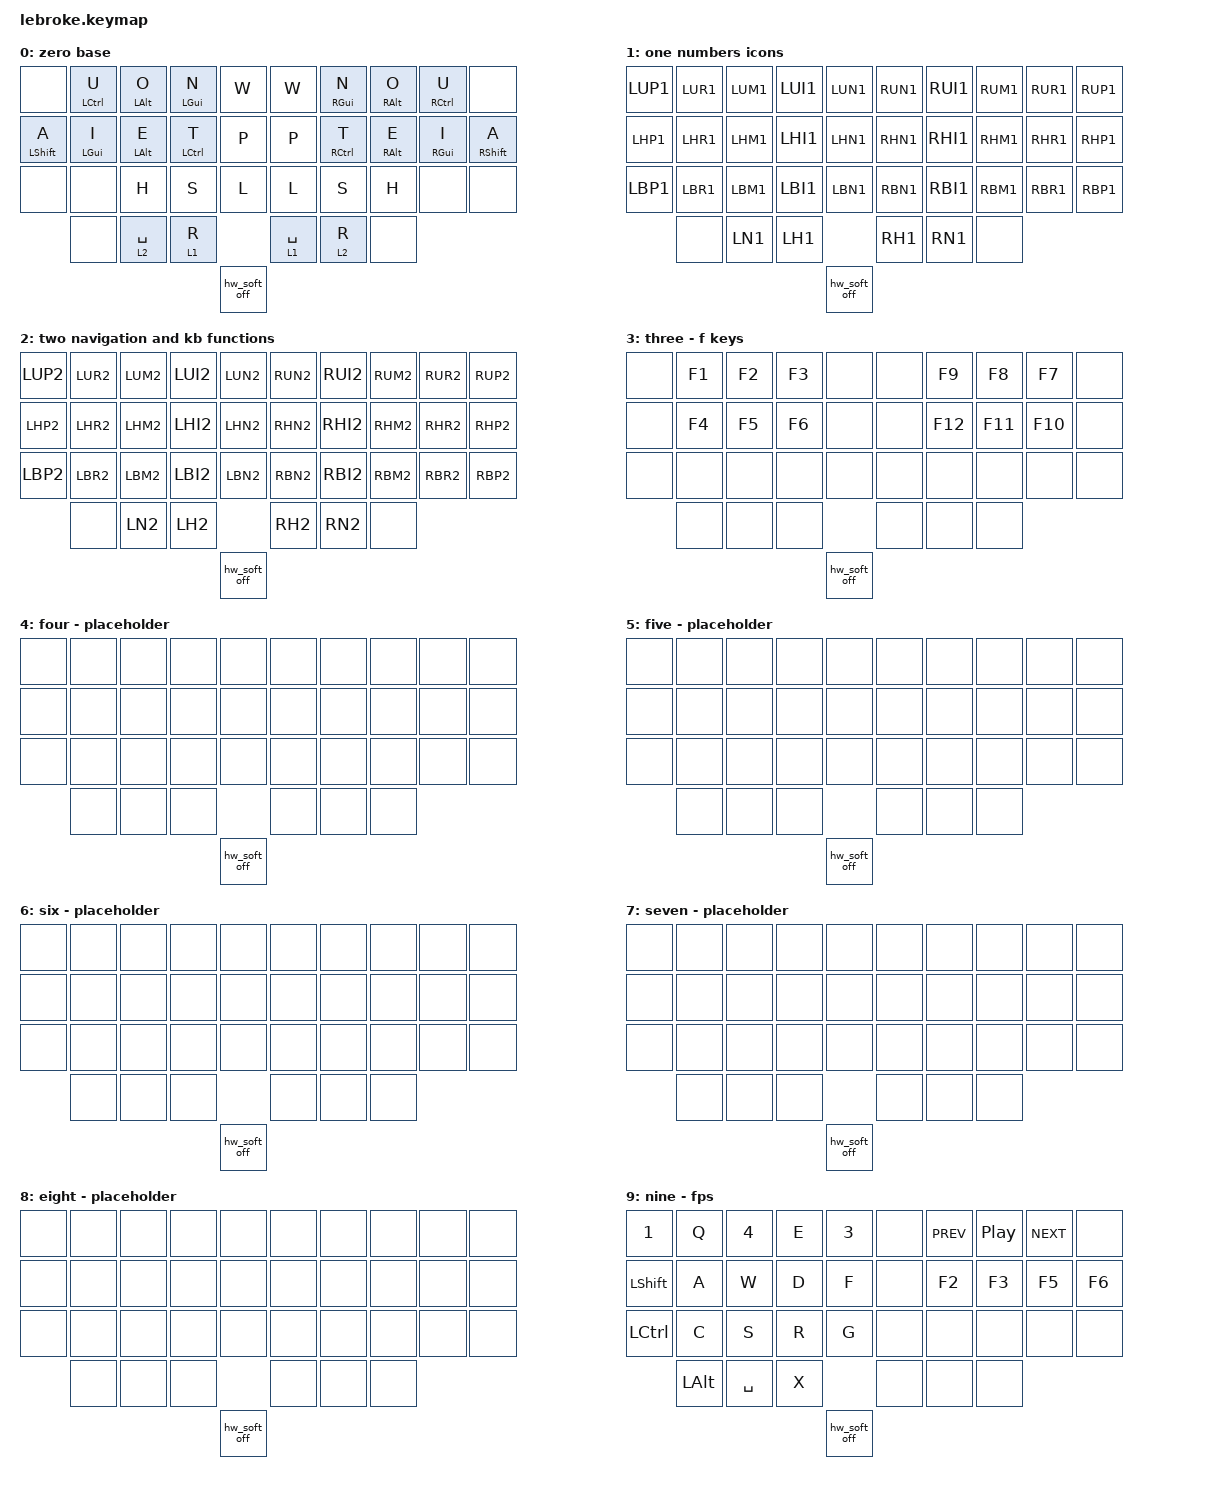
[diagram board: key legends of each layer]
#include "fingermap.h"

/ {
	behaviors {
		hml: home_row_mod_left {
            		hold-trigger-key-positions = <5 6 7 8 9 15 16 17 18 19 25 26 27 28 29 33 34 35>; // List of keys on the right
        	};
        	hmr: home_row_mod_right {
            		hold-trigger-key-positions = <0 1 2 3 4 10 11 12 13 14 20 21 22 23 24 30 31 32>; // List of keys on the left
       		};
	};
	keymap {
		compatible = "zmk,keymap";
		zero {
			display-name = "zero base";
			bindings = <
				&none &hml LCTRL U &hml LALT O &hml LGUI N &kp W &kp W &hmr RGUI N &hmr RALT O &hmr RCTRL U &none
				&hml LSHIFT A &hml LGUI I &hml LALT E &hml LCTRL T &kp P &kp P &hmr RCTRL T &hmr RALT E &hmr RGUI I &hmr RSHIFT A
				&none &none &kp H &kp S &kp L &kp L &kp S &kp H &none &none
				&none &lt 2 SPACE &lt 1 R &lt 1 SPACE &lt 2 R &none
									&hw_soft_off
			>;
		};
		one { display-name = "one numbers icons";
			bindings = <
				LUP1 LUR1 LUM1 LUI1 LUN1 RUN1 RUI1 RUM1 RUR1 RUP1
				LHP1 LHR1 LHM1 LHI1 LHN1 RHN1 RHI1 RHM1 RHR1 RHP1
				LBP1 LBR1 LBM1 LBI1 LBN1 RBN1 RBI1 RBM1 RBR1 RBP1
					   &none LN1 LH1 RH1 RN1 &none 	
									&hw_soft_off
			>;
		};
		two { display-name = "two navigation and kb functions";
			bindings = <
				LUP2 LUR2 LUM2 LUI2 LUN2 RUN2 RUI2 RUM2 RUR2 RUP2
				LHP2 LHR2 LHM2 LHI2 LHN2 RHN2 RHI2 RHM2 RHR2 RHP2
				LBP2 LBR2 LBM2 LBI2 LBN2 RBN2 RBI2 RBM2 RBR2 RBP2
					   &none LN2 LH2 RH2 RN2 &none 	
									&hw_soft_off
			>;
		};
		three { display-name = "three - f keys";
			bindings = <
				&none &kp F1 &kp F2 &kp F3 &none &none &kp F9 &kp F8 &kp F7 &none
				&none &kp F4 &kp F5 &kp F6 &none &none &kp F12 &kp F11 &kp F10 &none
				&none &none &none &none &none &none &none &none &none &none
				&none &none &none &none &none &none &hw_soft_off
			>;
		};
		four { display-name = "four - placeholder";
			bindings = <
				&none &none &none &none &none &none &none &none &none &none
				&none &none &none &none &none &none &none &none &none &none
				&none &none &none &none &none &none &none &none &none &none
				&none &none &none &none &none &none &hw_soft_off
			>;
		};
		five { display-name = "five - placeholder";
			bindings = <
				&none &none &none &none &none &none &none &none &none &none
				&none &none &none &none &none &none &none &none &none &none
				&none &none &none &none &none &none &none &none &none &none
				&none &none &none &none &none &none &hw_soft_off
			>;
		};
		six { display-name = "six - placeholder";
			bindings = <
				&none &none &none &none &none &none &none &none &none &none
				&none &none &none &none &none &none &none &none &none &none
				&none &none &none &none &none &none &none &none &none &none
				&none &none &none &none &none &none &hw_soft_off
			>;
		};
		seven { display-name = "seven - placeholder";
			bindings = <
				&none &none &none &none &none &none &none &none &none &none
				&none &none &none &none &none &none &none &none &none &none
				&none &none &none &none &none &none &none &none &none &none
				&none &none &none &none &none &none &hw_soft_off
			>;
		};
		eight { display-name = "eight - placeholder";
			bindings = <
				&none &none &none &none &none &none &none &none &none &none
				&none &none &none &none &none &none &none &none &none &none
				&none &none &none &none &none &none &none &none &none &none
				&none &none &none &none &none &none &hw_soft_off
			>;
		};
		nine { display-name = "nine - fps";
			bindings = <
				&kp N1 &kp Q &kp N4 &kp E &kp N3 		&none &kp C_PREV &kp C_PP &kp C_NEXT &none
				&kp LSHIFT &kp A &kp W &kp D &kp F 		&none &kp F2 &kp F3 &kp F5 &kp F6
				&kp LCTRL &kp C &kp S &kp R &kp G		&none &none &none &none &none
				&kp LALT &kp SPACE &kp X 			&none &none &none &hw_soft_off
			>;
		};
	};
};

/ {
	combos {
		compatible = "zmk,combos";

// keyboard functions
		combo_bt_zero {
			timeout-ms = <50>;
			key-positions = <10 11 12 13>;
			bindings = <&bluetooth0>;
			layers = <0>;
		};
		combo_bt_one {
			timeout-ms = <50>;
			key-positions = <16 17 18 19>;
			bindings = <&bluetooth1>;
			layers = <0>;
		};
		combo_usb {
			timeout-ms = <50>;
			key-positions = <22 23 26 27>;
			bindings = <&out OUT_USB>;
			layers = <0>;
		};
		combo_fps_layer {
			timeout-ms = <50>;
			key-positions = <11 12 13>;
			bindings = <&to 9>;
			layers = <0>;
		};
		combo_default_layer {
			timeout-ms = <50>;
			key-positions = <12 13 16 17>;
			bindings = <&to 0>;
		};
// mod keys


		combo_lhp_lhr {
			timeout-ms = <50>;
			key-positions = <10 11>;
			bindings = <LHO>;
			layers = <0 1 2>;
		};
		combo_lur_lui {
			timeout-ms = <50>;
			key-positions = <1 3>;
			bindings = <LUO>;
		};
		combo_rui_rur {
			timeout-ms = <50>;
			key-positions = <6 8>;
			bindings = <RUO>;
		};
		combo_rhr_rhp {
			timeout-ms = <50>;
			key-positions = <18 19>;
			bindings = <RHO>;
			layers = <0 1 2>;
		};


		combo_enter {
			timeout-ms = <50>;
			key-positions = <13 16>;
			bindings = <&kp ENTER>;
			layers = <0 1 2>;
		};
		combo_capsword {
			timeout-ms = <50>;
			key-positions = <10 19>;
			bindings = <&caps_word>;
			layers = <0>;
		};

// arrow keys
		combo_up {
			timeout-ms = <50>;
			key-positions = <12 17>;
			bindings = <&kp UP>;
		};
		combo_left {
			timeout-ms = <50>;
			key-positions = <11 16>;
			bindings = <&kp LEFT>;
		};
		combo_down {
			timeout-ms = <50>;
			key-positions = <22 27>;
			bindings = <&kp DOWN>;
		};
		combo_right {
			timeout-ms = <50>;
			key-positions = <13 18>;
			bindings = <&kp RIGHT>;
		};
// game 
		combo_b_game {
			timeout-ms = <90>;
			key-positions = <22 23>;
			bindings = <&kp B>;
			layers = <9>;
		};
		combo_k_game {
			timeout-ms = <90>;
			key-positions = <10 31>;
			bindings = <&kp K>;
			layers = <9>;
		};
  		combo_left_y {
			timeout-ms = <35>;
			key-positions = <1 2>;
			bindings = <&kp Y>;
			layers = <0>;
		};
		combo_left_m {
			timeout-ms = <35>;
			key-positions = <2 3>;
			bindings = <&kp M>;
			layers = <0>;
		};
		combo_left_x {
			timeout-ms = <50>;
			key-positions = <1 10>;
			bindings = <&kp X>;
			layers = <0>;
		};
		combo_left_j {
			timeout-ms = <65>;
			key-positions = <1 11>;
			bindings = <&kp J>;
			layers = <0>;
		};
		combo_left_k {
			timeout-ms = <65>;
			key-positions = <2 12>;
			bindings = <&kp K>;
			layers = <0>;
		};
		combo_left_f {
			timeout-ms = <50>;
			key-positions = <2 13>;
			bindings = <&kp F>;
			layers = <0>;
		};
		combo_left_g {
			timeout-ms = <50>;
			key-positions = <11 12>;
			bindings = <&kp G>;
			layers = <0>;
		};
		combo_left_c {
			timeout-ms = <50>;
			key-positions = <12 13>;
			bindings = <&kp C>;
			layers = <0>;
		}; 
		combo_left_qu {
			timeout-ms = <65>;
			key-positions = <12 22>;
			bindings = <&qu>;
			layers = <0>;
		};
		combo_left_v {
			timeout-ms = <50>;
			key-positions = <12 23>;
			bindings = <&kp V>;
			layers = <0>;
		};
		combo_left_b {
			timeout-ms = <65>;
			key-positions = <13 23>;
			bindings = <&kp B>;
			layers = <0>;
		};
		combo_left_d {
			timeout-ms = <50>;
			key-positions = <22 23>;
			bindings = <&kp D>;
			layers = <0>;
		};
		combo_left_z {
			timeout-ms = <50>;
			key-positions = <10 32>;
			bindings = <&lt 2 Z>;
			layers = <0>;
		};



		combo_right_y {
			timeout-ms = <35>;
			key-positions = <7 8>;
			bindings = <&kp Y>;
			layers = <0>;
		};
		combo_right_m {
			timeout-ms = <35>;
			key-positions = <6 7>;
			bindings = <&kp M>;
			layers = <0>;
		};
		combo_right_x {
			timeout-ms = <50>;
			key-positions = <8 19>;
			bindings = <&kp X>;
			layers = <0>;
		};
		combo_right_j {
			timeout-ms = <65>;
			key-positions = <8 18>;
			bindings = <&kp J>;
			layers = <0>;
		};
		combo_right_k {
			timeout-ms = <65>;
			key-positions = <7 17>;
			bindings = <&kp K>;
			layers = <0>;
		};
		combo_right_f {
			timeout-ms = <50>;
			key-positions = <7 16>;
			bindings = <&kp F>;
			layers = <0>;
		};
		combo_right_g {
			timeout-ms = <50>;
			key-positions = <17 18>;
			bindings = <&kp G>;
			layers = <0>;
		};
		combo_right_c {
			timeout-ms = <50>;
			key-positions = <16 17>;
			bindings = <&kp C>;
			layers = <0>;
		};
		combo_right_qu {
			timeout-ms = <65>;
			key-positions = <17 27>;
			bindings = <&qu>;
			layers = <0>;
		};
		combo_right_v {
			timeout-ms = <50>;
			key-positions = <17 26>;
			bindings = <&kp V>;
			layers = <0>;
		};
		combo_right_b {
			timeout-ms = <65>;
			key-positions = <16 26>;
			bindings = <&kp B>;
			layers = <0>;
		};
		combo_right_d {
			timeout-ms = <50>;
			key-positions = <26 27>;
			bindings = <&kp D>;
			layers = <0>;
		};
		combo_right_z {
			timeout-ms = <50>;
			key-positions = <19 33>;
			bindings = <&lt 2 Z>;
			layers = <0>;
		};
	};
};
